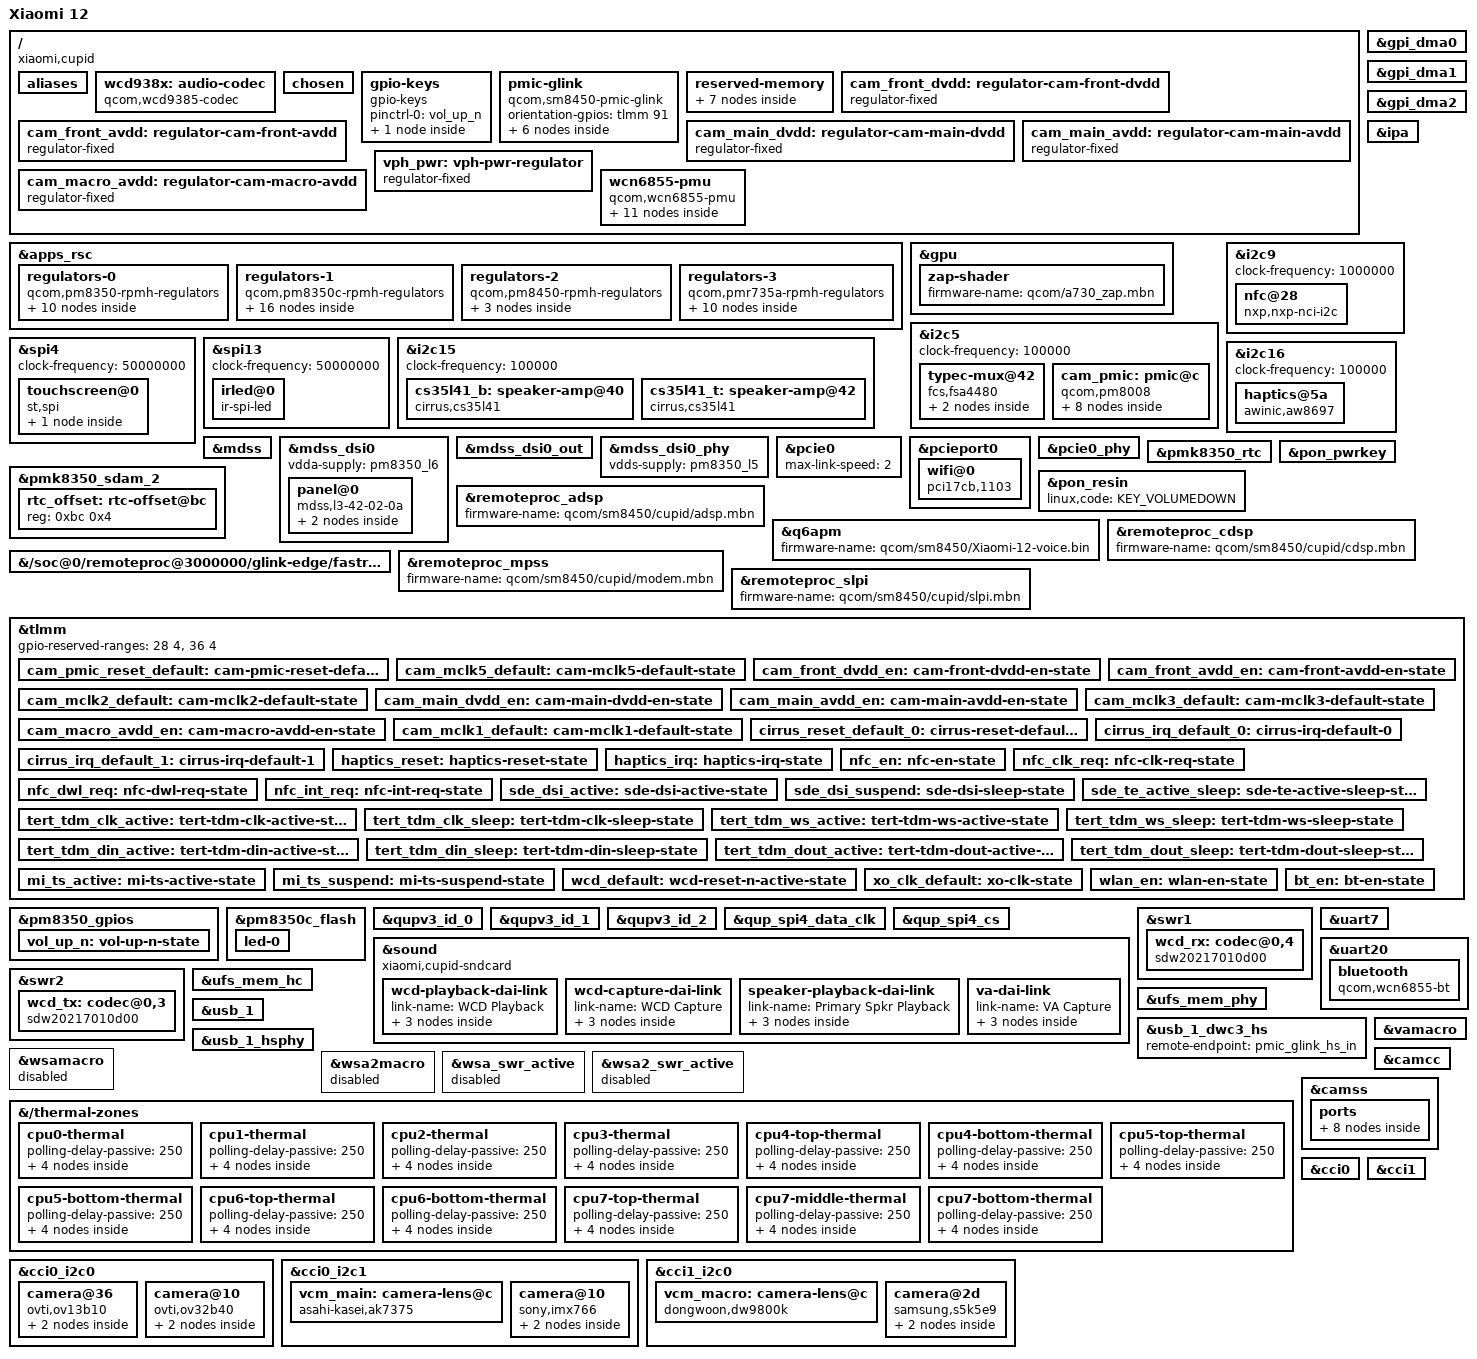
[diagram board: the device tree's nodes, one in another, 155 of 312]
// SPDX-License-Identifier: GPL-2.0-only
/dts-v1/;

#include <dt-bindings/regulator/qcom,rpmh-regulator.h>
#include <dt-bindings/leds/common.h>
#include <dt-bindings/media/video-interfaces.h>
#include <dt-bindings/thermal/thermal.h>

#include "sm8450.dtsi"
#include "pm8350.dtsi"
#include "pm8350b.dtsi"
#include "pm8350c.dtsi"
#include "pm8450.dtsi"
#include "pmk8350.dtsi"
#include "pmr735a.dtsi"

/delete-node/ &xbl_ramdump_mem;
/delete-node/ &xbl_sc_mem2;
/delete-node/ &adsp_mem;
/delete-node/ &rmtfs_mem;

/ {
	model = "Xiaomi 12";
	compatible = "xiaomi,cupid", "qcom,sm8450";
	chassis-type = "handset";

	/*
	 * Qualcomm's ABL matches these against SMEM before it will boot a dtb.
	 * Copied verbatim from the stock cupid devicetree. Without them the
	 * bootloader resets in a loop without any output.
	 */
	qcom,msm-id = <457 0x20000 482 0x20000 457 0x10000 482 0x10000>;
	qcom,board-id = <0x10008 0>;

	aliases {
		hsuart0 = &uart20;
		serial0 = &uart7;
	};

	wcd938x: audio-codec {
		compatible = "qcom,wcd9385-codec";

		pinctrl-names = "default";
		pinctrl-0 = <&wcd_default>;

		qcom,micbias1-microvolt = <2750000>;
		qcom,micbias2-microvolt = <2750000>;
		qcom,micbias3-microvolt = <2750000>;
		qcom,micbias4-microvolt = <2750000>;
		qcom,mbhc-buttons-vthreshold-microvolt = <75000 150000 237000 500000 500000 500000 500000 500000>;
		qcom,mbhc-headset-vthreshold-microvolt = <1700000>;
		qcom,mbhc-headphone-vthreshold-microvolt = <50000>;
		qcom,rx-device = <&wcd_rx>;
		qcom,tx-device = <&wcd_tx>;

		reset-gpios = <&tlmm 43 GPIO_ACTIVE_LOW>;

		vdd-buck-supply = <&pm8350_s10>;
		vdd-rxtx-supply = <&pm8350_s10>;
		vdd-io-supply = <&pm8350_s10>;
		vdd-mic-bias-supply = <&vreg_bob>;

		#sound-dai-cells = <1>;
	};

	chosen {
		#address-cells = <2>;
		#size-cells = <2>;
		ranges;

		bootargs = "earlycon clk_ignore_unused pd_ignore_unused console=tty0";
		stdout-path = "serial0:115200n8";
	};

	gpio-keys {
		compatible = "gpio-keys";

		pinctrl-0 = <&vol_up_n>;
		pinctrl-names = "default";

		key-volume-up {
			label = "Volume Up";
			linux,code = <KEY_VOLUMEUP>;
			gpios = <&pm8350_gpios 6 GPIO_ACTIVE_LOW>;
			debounce-interval = <15>;
			linux,can-disable;
			wakeup-source;
		};
	};

	pmic-glink {
		compatible = "qcom,sm8450-pmic-glink", "qcom,pmic-glink";
		#address-cells = <1>;
		#size-cells = <0>;
		orientation-gpios = <&tlmm 91 GPIO_ACTIVE_HIGH>;

		connector@0 {
			compatible = "usb-c-connector";
			reg = <0>;
			power-role = "dual";
			data-role = "dual";

			ports {
				#address-cells = <1>;
				#size-cells = <0>;

				port@0 {
					reg = <0>;

					pmic_glink_hs_in: endpoint {
						remote-endpoint = <&usb_1_dwc3_hs>;
					};
				};

				// USB3 not present, so no port@1

				port@2 {
					reg = <2>;

					pmic_glink_sbu: endpoint {
						remote-endpoint = <&fsa4480_sbu_mux>;
					};
				};
			};
		};
	};

	reserved-memory {
		/*
		 * Heap of the ADSP's static audio PD, handed over when the PD
		 * is created (FASTRPC_IOCTL_INIT_CREATE_STATIC "audiopd"). The
		 * audio PD loads dynamic modules such as the voice ECNS from
		 * the DSP partition through it. fastrpc assigns the whole
		 * region to LPASS/ADSP_HEAP at probe, so it must be no-map:
		 * as a reusable (CMA) pool like on kodiak, the page allocator
		 * kept lending its pages to Linux, and touching one ended in a
		 * synchronous external abort (crashes under memory pressure).
		 */
		adsp_rpc_remote_heap_mem: adsp-rpc-remote-heap {
			alloc-ranges = <0x0 0x80000000 0x0 0x80000000>;
			alignment = <0x0 0x400000>;
			size = <0x0 0x800000>;
			no-map;
		};

		xbl_ramdump_mem: memory@a6b80000 {
			reg = <0x0 0xa6b80000 0x0 0x280000>;
			no-map;
		};

		xbl_sc_mem2: memory@a6e00000 {
			reg = <0x0 0xa6e00000 0x0 0x40000>;
			no-map;
		};

		adsp_mem: memory@9fd00000 {
			reg = <0x0 0x9fd00000 0x0 0x3100000>;
			no-map;
		};

		/*
		 * The rmtfs memory region in downstream is 'dynamically allocated'
		 * but given the same address every time. Hard code it as this address is
		 * where the modem firmware expects it to be.
		 */
		rmtfs_mem: memory@fe200000 {
			compatible = "qcom,rmtfs-mem";
			reg = <0x0 0xfe200000 0x0 0x280000>;
			no-map;

			qcom,client-id = <1>;
			qcom,vmid = <QCOM_SCM_VMID_MSS_MSA>;
		};

		splash_region@b8000000 {
			reg = <0x0 0xb8000000 0x0 0x2b00000>;
			no-map;
		};

		ramoops@a7000000 {
			compatible = "ramoops";
			reg = <0 0xa7000000 0x0 0x400000>;
			console-size = <0x200000>;
			pmsg-size = <0x200000>;
			ecc-size = <16>;
			no-map;
		};
	};

	/* front camera rails, external LDOs switched by TLMM (stock CAMERA_F_DVDD/AVDD) */
	cam_front_dvdd: regulator-cam-front-dvdd {
		compatible = "regulator-fixed";
		regulator-name = "cam_front_dvdd";
		regulator-min-microvolt = <1100000>;
		regulator-max-microvolt = <1100000>;
		gpio = <&tlmm 93 GPIO_ACTIVE_HIGH>;
		enable-active-high;
		vin-supply = <&pm8350_s12>;
		pinctrl-0 = <&cam_front_dvdd_en>;
		pinctrl-names = "default";
	};

	cam_front_avdd: regulator-cam-front-avdd {
		compatible = "regulator-fixed";
		regulator-name = "cam_front_avdd";
		regulator-min-microvolt = <2800000>;
		regulator-max-microvolt = <2800000>;
		gpio = <&tlmm 68 GPIO_ACTIVE_HIGH>;
		enable-active-high;
		vin-supply = <&vreg_bob>;
		pinctrl-0 = <&cam_front_avdd_en>;
		pinctrl-names = "default";
	};

	/* main camera rails, external LDOs switched by TLMM (stock CAMERA_W_DVDD/AVDD) */
	cam_main_dvdd: regulator-cam-main-dvdd {
		compatible = "regulator-fixed";
		regulator-name = "cam_main_dvdd";
		regulator-min-microvolt = <1104000>;
		regulator-max-microvolt = <1104000>;
		gpio = <&tlmm 2 GPIO_ACTIVE_HIGH>;
		enable-active-high;
		vin-supply = <&pm8350_s12>;
		pinctrl-0 = <&cam_main_dvdd_en>;
		pinctrl-names = "default";
	};

	cam_main_avdd: regulator-cam-main-avdd {
		compatible = "regulator-fixed";
		regulator-name = "cam_main_avdd";
		regulator-min-microvolt = <1800000>;
		regulator-max-microvolt = <1800000>;
		gpio = <&tlmm 70 GPIO_ACTIVE_HIGH>;
		enable-active-high;
		vin-supply = <&pm8350c_s1>;
		pinctrl-0 = <&cam_main_avdd_en>;
		pinctrl-names = "default";
	};

	/* telemacro analog, external LDO switched by TLMM (stock CAMERA_M_AVDD) */
	cam_macro_avdd: regulator-cam-macro-avdd {
		compatible = "regulator-fixed";
		regulator-name = "cam_macro_avdd";
		regulator-min-microvolt = <2800000>;
		regulator-max-microvolt = <2800000>;
		gpio = <&tlmm 71 GPIO_ACTIVE_HIGH>;
		enable-active-high;
		vin-supply = <&vreg_bob>;
		pinctrl-0 = <&cam_macro_avdd_en>;
		pinctrl-names = "default";
	};

	vph_pwr: vph-pwr-regulator {
		compatible = "regulator-fixed";
		regulator-name = "vph_pwr";
		regulator-min-microvolt = <3700000>;
		regulator-max-microvolt = <3700000>;

		regulator-always-on;
		regulator-boot-on;
	};

	wcn6855-pmu {
		compatible = "qcom,wcn6855-pmu";

		pinctrl-0 = <&bt_en>, <&wlan_en>, <&xo_clk_default>;
		pinctrl-names = "default";

		wlan-enable-gpios = <&tlmm 80 GPIO_ACTIVE_HIGH>;
		bt-enable-gpios = <&tlmm 81 GPIO_ACTIVE_HIGH>;
		/*
		 * XO clock select handshake (stock cnss: qcom,xo-clk-gpio on
		 * gpio204). 7.x's power sequencer drives it around WLAN enable;
		 * without it the chip's boot ROM never took the firmware image
		 * ("MHI did not load image over BHI").
		 */
		xo-clk-gpios = <&tlmm 204 GPIO_ACTIVE_HIGH>;
		swctrl-gpios = <&tlmm 82 GPIO_ACTIVE_HIGH>;

		vddio-supply = <&pm8350_s10>;
		/* stock vdd-wlan-dig (0.95 V); pmr735a_s2 is vdd-wlan-aon -> vddpmumx */
		vddaon-supply = <&pm8350_s11>;
		vddpmu-supply = <&pm8350_s11>;
		vddpmumx-supply = <&pmr735a_s2>;
		vddpmucx-supply = <&pm8350_s11>;
		vddrfa0p95-supply = <&pm8350_s11>;
		vddrfa1p3-supply = <&pm8350_s12>;
		vddrfa1p9-supply = <&pm8350c_s1>;
		vddpcie1p3-supply = <&pm8350_s12>;
		vddpcie1p9-supply = <&pm8350c_s1>;

		regulators {
			vreg_pmu_rfa_cmn_0p8: ldo0 {
				regulator-name = "vreg_pmu_rfa_cmn_0p8";
			};

			vreg_pmu_aon_0p8: ldo1 {
				regulator-name = "vreg_pmu_aon_0p8";
			};

			vreg_pmu_wlcx_0p8: ldo2 {
				regulator-name = "vreg_pmu_wlcx_0p8";
			};

			vreg_pmu_wlmx_0p8: ldo3 {
				regulator-name = "vreg_pmu_wlmx_0p8";
			};

			vreg_pmu_btcmx_0p8: ldo4 {
				regulator-name = "vreg_pmu_btcmx_0p8";
			};

			vreg_pmu_pcie_1p8: ldo5 {
				regulator-name = "vreg_pmu_pcie_1p8";
			};

			vreg_pmu_pcie_0p9: ldo6 {
				regulator-name = "vreg_pmu_pcie_0p9";
			};

			vreg_pmu_rfa_0p8: ldo7 {
				regulator-name = "vreg_pmu_rfa_0p8";
			};

			vreg_pmu_rfa_1p2: ldo8 {
				regulator-name = "vreg_pmu_rfa_1p2";
			};

			vreg_pmu_rfa_1p7: ldo9 {
				regulator-name = "vreg_pmu_rfa_1p7";
			};
		};
	};
};


&apps_rsc {
	regulators-0 {
		compatible = "qcom,pm8350-rpmh-regulators";
		qcom,pmic-id = "b";

		vdd-s1-supply = <&vph_pwr>;
		vdd-s2-supply = <&vph_pwr>;
		vdd-s3-supply = <&vph_pwr>;
		vdd-s4-supply = <&vph_pwr>;
		vdd-s5-supply = <&vph_pwr>;
		vdd-s6-supply = <&vph_pwr>;
		vdd-s7-supply = <&vph_pwr>;
		vdd-s8-supply = <&vph_pwr>;
		vdd-s9-supply = <&vph_pwr>;
		vdd-s10-supply = <&vph_pwr>;
		vdd-s11-supply = <&vph_pwr>;
		vdd-s12-supply = <&vph_pwr>;

		vdd-l1-l4-supply = <&pm8350_s11>;
		vdd-l2-l7-supply = <&vreg_bob>;
		vdd-l3-l5-supply = <&pm8350_s11>;
		vdd-l6-l9-l10-supply = <&pm8350_s12>;

		/*
		 * ARC regulators:
		 * s5 - gfx.lvl
		 * l8 - lcx.lvl
		 */

		pm8350_s10: smps10 {
			regulator-name = "pm8350_s10";
			regulator-min-microvolt = <1800000>;
			regulator-max-microvolt = <1800000>;

			/* WCN6855 rail: keep up so the PCIe link trains with the chip powered */
			regulator-always-on;
			regulator-boot-on;
		};

		/*
		 * WCN6855 rails at the stock/HDK minimums (vdd-wlan-dig 0.966 V,
		 * vdd-wlan-rfa2 1.35 V). With 0.848/1.224 V the regulators sat at
		 * their minimum on 7.x, the chip enumerated, then dropped off the
		 * link while booting its firmware ("MHI did not load image over
		 * BHI" / "Device link is not accessible").
		 */
		pm8350_s11: smps11 {
			regulator-name = "pm8350_s11";
			regulator-min-microvolt = <966000>;
			regulator-max-microvolt = <1104000>;

			/* WCN6855 rail: keep up so the PCIe link trains with the chip powered */
			regulator-always-on;
			regulator-boot-on;
		};

		pm8350_s12: smps12 {
			regulator-name = "pm8350_s12";
			regulator-min-microvolt = <1350000>;
			regulator-max-microvolt = <1400000>;

			/* WCN6855 rail: keep up so the PCIe link trains with the chip powered */
			regulator-always-on;
			regulator-boot-on;
		};

		pm8350_l1: ldo1 {
			regulator-name = "pm8350_l1";
			regulator-min-microvolt = <912000>;
			regulator-max-microvolt = <920000>;
			regulator-initial-mode = <RPMH_REGULATOR_MODE_HPM>;
		};

		pm8350_l2: ldo2 {
			regulator-name = "pm8350_l2";
			regulator-min-microvolt = <3072000>;
			regulator-max-microvolt = <3072000>;
			regulator-initial-mode = <RPMH_REGULATOR_MODE_HPM>;
		};

		pm8350_l3: ldo3 {
			regulator-name = "pm8350_l3";
			regulator-min-microvolt = <904000>;
			regulator-max-microvolt = <904000>;
			regulator-initial-mode = <RPMH_REGULATOR_MODE_HPM>;
		};

		pm8350_l5: ldo5 {
			regulator-name = "pm8350_l5";
			regulator-min-microvolt = <880000>;
			regulator-max-microvolt = <912000>;
			regulator-initial-mode = <RPMH_REGULATOR_MODE_HPM>;
		};

		pm8350_l6: ldo6 {
			regulator-name = "pm8350_l6";
			regulator-min-microvolt = <1200000>;
			regulator-max-microvolt = <1200000>;
			regulator-initial-mode = <RPMH_REGULATOR_MODE_HPM>;
		};

		pm8350_l7: ldo7 {
			regulator-name = "pm8350_l7";
			regulator-min-microvolt = <2504000>;
			regulator-max-microvolt = <2504000>;
			regulator-initial-mode = <RPMH_REGULATOR_MODE_HPM>;
		};

		pm8350_l9: ldo9 {
			regulator-name = "pm8350_l9";
			regulator-min-microvolt = <1200000>;
			regulator-max-microvolt = <1200000>;
			regulator-initial-mode = <RPMH_REGULATOR_MODE_HPM>;
		};
	};

	regulators-1 {
		compatible = "qcom,pm8350c-rpmh-regulators";
		qcom,pmic-id = "c";

		vdd-s1-supply = <&vph_pwr>;
		vdd-s2-supply = <&vph_pwr>;
		vdd-s3-supply = <&vph_pwr>;
		vdd-s4-supply = <&vph_pwr>;
		vdd-s5-supply = <&vph_pwr>;
		vdd-s6-supply = <&vph_pwr>;
		vdd-s7-supply = <&vph_pwr>;
		vdd-s8-supply = <&vph_pwr>;
		vdd-s9-supply = <&vph_pwr>;
		vdd-s10-supply = <&vph_pwr>;

		vdd-l1-l12-supply = <&pm8350c_s1>;
		vdd-l2-l8-supply = <&pm8350c_s1>;
		vdd-l3-l4-l5-l7-l13-supply = <&vreg_bob>;
		vdd-l6-l9-l11-supply = <&vreg_bob>;
		vdd-l10-supply = <&pm8350_s12>;

		vdd-bob-supply = <&vph_pwr>;

		/*
		 * ARC regulators:
		 * s2 - mxc.lvl
		 * s4 - mss.lvl
		 * s6 - cx.lvl
		 */

		pm8350c_s1: smps1 {
			regulator-name = "pm8350c_s1";
			regulator-min-microvolt = <1800000>;
			regulator-max-microvolt = <2024000>;

			/* WCN6855 rail: keep up so the PCIe link trains with the chip powered */
			regulator-always-on;
			regulator-boot-on;
		};

		pm8350c_s10: smps10 {
			regulator-name = "pm8350c_s10";
			regulator-min-microvolt = <1000000>;
			regulator-max-microvolt = <1100000>;
		};

		vreg_bob: bob {
			regulator-name = "vreg_bob";
			regulator-min-microvolt = <3080000>;
			regulator-max-microvolt = <3960000>;
			regulator-initial-mode = <RPMH_REGULATOR_MODE_AUTO>;
		};

		pm8350c_l1: ldo1 {
			regulator-name = "pm8350c_l1";
			regulator-min-microvolt = <1800000>;
			regulator-max-microvolt = <1800000>;
			regulator-initial-mode = <RPMH_REGULATOR_MODE_HPM>;
		};

		pm8350c_l2: ldo2 {
			regulator-name = "pm8350c_l2";
			regulator-min-microvolt = <1800000>;
			regulator-max-microvolt = <1800000>;
			regulator-initial-mode = <RPMH_REGULATOR_MODE_HPM>;

			/* touchscreen vdd: the fts driver never takes a reference on it */
			regulator-always-on;
			regulator-boot-on;
		};

		pm8350c_l3: ldo3 {
			regulator-name = "pm8350c_l3";
			regulator-min-microvolt = <3296000>;
			regulator-max-microvolt = <3304000>;
			regulator-initial-mode = <RPMH_REGULATOR_MODE_HPM>;
		};

		pm8350c_l4: ldo4 {
			regulator-name = "pm8350c_l4";
			regulator-min-microvolt = <1704000>;
			regulator-max-microvolt = <3000000>;
			regulator-initial-mode = <RPMH_REGULATOR_MODE_HPM>;
		};

		pm8350c_l5: ldo5 {
			regulator-name = "pm8350c_l5";
			regulator-min-microvolt = <1704000>;
			regulator-max-microvolt = <3000000>;
			regulator-initial-mode = <RPMH_REGULATOR_MODE_HPM>;
		};

		pm8350c_l6: ldo6 {
			regulator-name = "pm8350c_l6";
			regulator-min-microvolt = <1800000>;
			/* Originally max = 3008000 but SDHCI expects 2960000 */
			regulator-max-microvolt = <2960000>;
			regulator-initial-mode = <RPMH_REGULATOR_MODE_HPM>;
		};

		pm8350c_l7: ldo7 {
			regulator-name = "pm8350c_l7";
			regulator-min-microvolt = <3008000>;
			regulator-max-microvolt = <3304000>;
			regulator-initial-mode = <RPMH_REGULATOR_MODE_HPM>;

			/* touchscreen avdd */
			regulator-always-on;
			regulator-boot-on;
		};

		pm8350c_l8: ldo8 {
			regulator-name = "pm8350c_l8";
			regulator-min-microvolt = <1800000>;
			regulator-max-microvolt = <1800000>;
			regulator-initial-mode = <RPMH_REGULATOR_MODE_HPM>;
		};

		pm8350c_l9: ldo9 {
			regulator-name = "pm8350c_l9";
			regulator-min-microvolt = <2960000>;
			/* Originally max = 3008000 but SDHCI expects 2960000 */
			regulator-max-microvolt = <2960000>;
			regulator-initial-mode = <RPMH_REGULATOR_MODE_HPM>;
		};

		pm8350c_l10: ldo10 {
			regulator-name = "pm8350c_l10";
			regulator-min-microvolt = <1200000>;
			regulator-max-microvolt = <1220000>;
			regulator-initial-mode = <RPMH_REGULATOR_MODE_HPM>;
		};

		pm8350c_l11: ldo11 {
			regulator-name = "pm8350c_l11";
			regulator-min-microvolt = <3200000>;
			regulator-max-microvolt = <3200000>;
			regulator-initial-mode = <RPMH_REGULATOR_MODE_HPM>;

			regulator-always-on;
			regulator-boot-on;
		};

		pm8350c_l12: ldo12 {
			regulator-name = "pm8350c_l12";
			regulator-min-microvolt = <1800000>;
			regulator-max-microvolt = <1968000>;
			regulator-initial-mode = <RPMH_REGULATOR_MODE_HPM>;
		};

		pm8350c_l13: ldo13 {
			regulator-name = "pm8350c_l13";
			regulator-min-microvolt = <3000000>;
			regulator-max-microvolt = <3000000>;
			regulator-initial-mode = <RPMH_REGULATOR_MODE_HPM>;
		};
	};

	regulators-2 {
		compatible = "qcom,pm8450-rpmh-regulators";
		qcom,pmic-id = "h";

		vdd-s1-supply = <&vph_pwr>;
		vdd-s2-supply = <&vph_pwr>;
		vdd-s3-supply = <&vph_pwr>;
		vdd-s4-supply = <&vph_pwr>;
		vdd-s5-supply = <&vph_pwr>;
		vdd-s6-supply = <&vph_pwr>;

		vdd-l2-supply = <&vreg_bob>;
		vdd-l3-supply = <&vreg_bob>;
		vdd-l4-supply = <&vreg_bob>;

		/*
		 * ARC regulators:
		 * S2 - ebi.lvl
		 * S4 - mmcx.lvl
		 * S6 - mx.lvl
		 * L1 - lmx.lvl
		 */

		pm8450_s3: smps3 {
			regulator-name = "pm8450_s3";
			regulator-min-microvolt = <500000>;
			regulator-max-microvolt = <600000>;
		};

		pm8450_l2: ldo2 {
			regulator-name = "pm8450_l2";
			regulator-min-microvolt = <880000>;
			regulator-max-microvolt = <912000>;
			regulator-initial-mode = <RPMH_REGULATOR_MODE_HPM>;
		};

		pm8450_l3: ldo3 {
			regulator-name = "pm8450_l3";
			regulator-min-microvolt = <912000>;
			regulator-max-microvolt = <912000>;
			regulator-initial-mode = <RPMH_REGULATOR_MODE_HPM>;
		};
	};

	regulators-3 {
		compatible = "qcom,pmr735a-rpmh-regulators";
		qcom,pmic-id = "e";

		vdd-s1-supply = <&vph_pwr>;
		vdd-s2-supply = <&vph_pwr>;
		vdd-s3-supply = <&vph_pwr>;

		vdd-l1-l2-supply = <&pmr735a_s2>;
		vdd-l3-supply = <&pmr735a_s1>;
		vdd-l4-supply = <&pm8350c_s1>;
		vdd-l5-l6-supply = <&pm8350c_s1>;
		vdd-l7-bob-supply = <&vreg_bob>;

		pmr735a_s1: smps1 {
			regulator-name = "pmr735a_s1";
			regulator-min-microvolt = <1200000>;
			regulator-max-microvolt = <1296000>;
		};

		pmr735a_s2: smps2 {
			regulator-name = "pmr735a_s2";
			regulator-min-microvolt = <500000>;
			regulator-max-microvolt = <1040000>;

			/* WCN6855 rail: keep up so the PCIe link trains with the chip powered */
			regulator-always-on;
			regulator-boot-on;
		};

		pmr735a_s3: smps3 {
			regulator-name = "pmr735a_s3";
			regulator-min-microvolt = <435000>;
			regulator-max-microvolt = <2352000>;
		};

		pmr735a_l1: ldo1 {
			regulator-name = "pmr735a_l1";
			regulator-min-microvolt = <800000>;
			regulator-max-microvolt = <800000>;
		};

		pmr735a_l2: ldo2 {
			regulator-name = "pmr735a_l2";
			regulator-min-microvolt = <480000>;
			regulator-max-microvolt = <912000>;
		};

		pmr735a_l3: ldo3 {
			regulator-name = "pmr735a_l3";
			regulator-min-microvolt = <1200000>;
			regulator-max-microvolt = <1200000>;
		};

		pmr735a_l4: ldo4 {
			regulator-name = "pmr735a_l4";
			regulator-min-microvolt = <1776000>;
			regulator-max-microvolt = <1776000>;
		};

		pmr735a_l5: ldo5 {
			regulator-name = "pmr735a_l5";
			regulator-min-microvolt = <880000>;
			regulator-max-microvolt = <880000>;
		};

		pmr735a_l6: ldo6 {
			regulator-name = "pmr735a_l6";
			regulator-min-microvolt = <1200000>;
			regulator-max-microvolt = <1200000>;
		};

		pmr735a_l7: ldo7 {
			regulator-name = "pmr735a_l7";
			regulator-min-microvolt = <2800000>;
			regulator-max-microvolt = <2800000>;
		};
	};
};

&gpi_dma0 {
	status = "okay";
};

&gpi_dma1 {
	status = "okay";
};

&gpi_dma2 {
	status = "okay";
};

&gpu {
	status = "okay";

	zap-shader {
		firmware-name = "qcom/a730_zap.mbn";
	};
};

/*
 * IPA v5.1, the modem's data path (rmnet). Without it ModemManager sees the
 * QMI modem but "Failed to find a net port". The AP loads the GSI firmware
 * itself (stock: pas-id 15 "ipa_fws", IPA driver loads it), into the same
 * 0x8b900000 region the stock devicetree reserves. Needs kernel patches
 * 0012 (driver) and 0013 (sm8450.dtsi node).
 */
&ipa {
	qcom,gsi-loader = "self";
	memory-region = <&ipa_fw_mem>;
	firmware-name = "qcom/sm8450/cupid/ipa_fws.mbn";
	status = "okay";
};

&i2c5 {
	clock-frequency = <100000>;
	status = "okay";

	typec-mux@42 {
		compatible = "fcs,fsa4480";
		reg = <0x42>;

		interrupts-extended = <&tlmm 69 IRQ_TYPE_LEVEL_LOW>;

		vcc-supply = <&vreg_bob>;
		mode-switch;
		orientation-switch;

		port {
			fsa4480_sbu_mux: endpoint {
				remote-endpoint = <&pmic_glink_sbu>;
			};
		};
	};

	/* nq @ 64 */

	/*
	 * Camera PMIC "pm8008j" (stock: qcom,i2c-pmic at 0xc and 0xd). Its
	 * reset/enable line is gpio11 (stock pm8008j_active: output-high), no
	 * interrupt is wired. Supplies and LDO ranges from the stock DT; the
	 * second PM8008 ("i" at 0x8) feeds no camera and stays undescribed.
	 */
	cam_pmic: pmic@c {
		compatible = "qcom,pm8008";
		reg = <0xc>;

		reset-gpios = <&tlmm 11 GPIO_ACTIVE_LOW>;
		pinctrl-0 = <&cam_pmic_reset_default>;
		pinctrl-names = "default";

		vdd-l1-l2-supply = <&pm8350_s12>;
		vdd-l3-l4-supply = <&vreg_bob>;
		vdd-l5-supply = <&pm8350c_s1>;
		vdd-l6-supply = <&vreg_bob>;
		vdd-l7-supply = <&vreg_bob>;

		regulators {
			/* telemacro core */
			cam_l1: ldo1 {
				regulator-name = "pm8008j_l1";
				regulator-min-microvolt = <1200000>;
				regulator-max-microvolt = <1200000>;
			};

			/* ultra-wide core */
			cam_l2: ldo2 {
				regulator-name = "pm8008j_l2";
				regulator-min-microvolt = <1200000>;
				regulator-max-microvolt = <1200000>;
			};

			/* ultra-wide analog */
			cam_l3: ldo3 {
				regulator-name = "pm8008j_l3";
				regulator-min-microvolt = <2800000>;
				regulator-max-microvolt = <2800000>;
			};

			/* telemacro autofocus (stock: 2.808 V) */
			cam_l4: ldo4 {
				regulator-name = "pm8008j_l4";
				regulator-min-microvolt = <2808000>;
				regulator-max-microvolt = <2808000>;
			};

			/*
			 * I/O of all four sensors, and the pull-up rail of the
			 * CCI buses. Kept on: while it is off SDA/SCL sit low,
			 * and the first CCI transfer after it comes back times
			 * out (the OV13B10's reset write, so every stream after
			 * the first failed).
			 */
			cam_l5: ldo5 {
				regulator-name = "pm8008j_l5";
				regulator-min-microvolt = <1800000>;
				regulator-max-microvolt = <1800000>;
				regulator-always-on;
			};

			/*
			 * Main camera second analogue rail (stock cam_v_custom1,
			 * 3.1 V), also the OIS supply.
			 */
			cam_l6: ldo6 {
				regulator-name = "pm8008j_l6";
				regulator-min-microvolt = <3104000>;
				regulator-max-microvolt = <3104000>;
			};

			/* main camera autofocus (stock cam_vaf: 3.104 V) */
			cam_l7: ldo7 {
				regulator-name = "pm8008j_l7";
				regulator-min-microvolt = <3104000>;
				regulator-max-microvolt = <3104000>;
			};
		};
	};
};

&i2c9 {
	clock-frequency = <1000000>;
	status = "okay";

	/*
	 * NXP SN100T. Downstream drives it with the "qcom,sn-nci" driver;
	 * mainline talks NCI to it through nxp-nci-i2c, as on the Nothing
	 * Phone (2) (SM8475), which wires it to the same GPIOs.
	 * VDD is pm8350_s10, already always-on for the WCN6855.
	 */
	nfc@28 {
		compatible = "nxp,nxp-nci-i2c";
		reg = <0x28>;

		interrupts-extended = <&tlmm 46 IRQ_TYPE_EDGE_RISING>;

		enable-gpios = <&tlmm 34 GPIO_ACTIVE_HIGH>;
		firmware-gpios = <&tlmm 45 GPIO_ACTIVE_HIGH>;

		pinctrl-0 = <&nfc_en>, <&nfc_clk_req>, <&nfc_dwl_req>,
			    <&nfc_int_req>;
		pinctrl-names = "default";
	};
};

&spi4 {
	clock-frequency = <50000000>;
	status = "okay";

	touchscreen@0 {
		compatible = "st,spi";
		reg = <0x0>;
		interrupt-parent = <&tlmm>;
		interrupts = <21 IRQ_TYPE_LEVEL_LOW>;
		pinctrl-names = "pmx_ts_active", "pmx_ts_suspend";
		pinctrl-0 = <&mi_ts_active>;
		pinctrl-1 = <&mi_ts_suspend>;
		avdd-supply = <&pm8350c_l7>;
		vdd-supply = <&pm8350c_l2>;
		fts,pwr-reg-name = "avdd";
		fts,bus-reg-name = "vdd";
		fts,irq-gpio = <&tlmm 21 IRQ_TYPE_LEVEL_LOW>;
		fts,reset-gpio-enable;
		fts,reset-gpio = <&tlmm 20 GPIO_ACTIVE_HIGH>;
		/*
		 * Passed straight to request_threaded_irq() with a NULL primary
		 * handler, which the core rejects without IRQF_ONESHOT:
		 * 0x2008 = IRQF_TRIGGER_LOW | IRQF_ONESHOT (same value as stock).
		 */
		fts,irq-flags = <0x2008>;
		fts,x-max = <10800>;
		fts,y-max = <24000>;
		fts,support-super-resolution = <1>;
		spi-max-frequency = <12000000>;
		fts,default-fw-name = "st_fts_l3.ftb";
		fts,config-array-size = <1>;

		fts,cfg_0 {
			fts,tp-vendor = <0x42>;
			fts,fw-name = "st_fts_l3.ftb";
			fts,limit-name = "stm_fts_production_limits.csv";
		};
	};
};

&spi13 {
	clock-frequency = <50000000>;
	status = "okay";

	irled@0 {
		compatible = "ir-spi-led";
		reg = <0x0>;
		power-supply = <&vph_pwr>;
		spi-max-frequency = <19200000>;
	};
};

&i2c15 {
	clock-frequency = <100000>;
	status = "okay";

	cs35l41_b: speaker-amp@40 {
		compatible = "cirrus,cs35l41";
		reg = <0x40>;
		interrupt-parent = <&tlmm>;
		interrupts = <118 0x2008>;
		pinctrl-names = "default";
		pinctrl-0 = <&cirrus_reset_default_0 &cirrus_irq_default_0>;
		reset-gpios = <&tlmm 1 GPIO_ACTIVE_HIGH>;
		cirrus,boost-peak-milliamp = <4000>;
		cirrus,boost-ind-nanohenry = <1000>;
		cirrus,boost-cap-microfarad = <15>;
		cirrus,gpio2-src-select = <4>;
		cirrus,gpio2-output-enable;
		cirrus,asp-sdout-hiz = <3>;
		sound-name-prefix = "SpkrRight";
		#sound-dai-cells = <1>;
	};

	cs35l41_t: speaker-amp@42 {
		compatible = "cirrus,cs35l41";
		reg = <0x42>;
		interrupt-parent = <&tlmm>;
		interrupts = <63 0x2008>;
		pinctrl-names = "default";
		pinctrl-0 = <&cirrus_irq_default_1>;
		reset-gpios = <&tlmm 1 GPIO_ACTIVE_HIGH>;
		cirrus,boost-peak-milliamp = <4000>;
		cirrus,boost-ind-nanohenry = <1000>;
		cirrus,boost-cap-microfarad = <15>;
		cirrus,gpio2-src-select = <4>;
		cirrus,gpio2-output-enable;
		cirrus,asp-sdout-hiz = <3>;
		sound-name-prefix = "SpkrLeft";
		#sound-dai-cells = <1>;
	};
};

&i2c16 {
	clock-frequency = <100000>;
	status = "okay";

	/*
	 * Awinic AW8697 LRA driver (patch 0019). The interrupt is described
	 * for completeness; the driver plays from the chip RAM and does not
	 * use it. The first driver version hung probe for 9 minutes on 6.13;
	 * the reworked one initialises from a work item and gives up on the
	 * first I2C error (tested on 7.3, 2026-11-16).
	 */
	haptics@5a {
		compatible = "awinic,aw8697";
		reg = <0x5a>;

		interrupts-extended = <&tlmm 90 IRQ_TYPE_EDGE_FALLING>;
		reset-gpios = <&tlmm 89 GPIO_ACTIVE_LOW>;

		pinctrl-0 = <&haptics_reset>, <&haptics_irq>;
		pinctrl-names = "default";
	};
};

&mdss {
	status = "okay";
};

&mdss_dsi0 {
	vdda-supply = <&pm8350_l6>;
	status = "okay";

	panel@0 {
		compatible = "mdss,l3-42-02-0a";
		reg = <0>;

		reset-gpios = <&tlmm 0 GPIO_ACTIVE_LOW>;
		te-gpios = <&tlmm 86 GPIO_ACTIVE_HIGH>;

		pinctrl-0 = <&sde_dsi_active &sde_te_active_sleep>;
		pinctrl-1 = <&sde_dsi_suspend &sde_te_active_sleep>;
		pinctrl-names = "default", "sleep";

		vddd-supply = <&pm8350c_l10>;
		vci-supply = <&pm8350c_l13>;
		vddio-supply = <&pm8350c_l12>;

		port {
			panel_in: endpoint {
				remote-endpoint = <&mdss_dsi0_out>;
			};
		};
	};
};

&mdss_dsi0_out {
	data-lanes = <0 1 2 3>;
	remote-endpoint = <&panel_in>;
};

&mdss_dsi0_phy {
	vdds-supply = <&pm8350_l5>;
	status = "okay";
};

&pcie0 {
	max-link-speed = <2>;
	status = "okay";
};

&pcieport0 {
	wifi@0 {
		compatible = "pci17cb,1103";
		reg = <0x10000 0x0 0x0 0x0 0x0>;

		vddrfacmn-supply = <&vreg_pmu_rfa_cmn_0p8>;
		vddaon-supply = <&vreg_pmu_aon_0p8>;
		vddwlcx-supply = <&vreg_pmu_wlcx_0p8>;
		vddwlmx-supply = <&vreg_pmu_wlmx_0p8>;
		vddpcie1p8-supply = <&vreg_pmu_pcie_1p8>;
		vddpcie0p9-supply = <&vreg_pmu_pcie_0p9>;
		vddrfa0p8-supply = <&vreg_pmu_rfa_0p8>;
		vddrfa1p2-supply = <&vreg_pmu_rfa_1p2>;
		vddrfa1p8-supply = <&vreg_pmu_rfa_1p7>;
	};
};

&pcie0_phy {
	vdda-phy-supply = <&pm8350_l5>;
	vdda-pll-supply = <&pm8350_l6>;
	status = "okay";
};

&pmk8350_rtc {
	nvmem-cells = <&rtc_offset>;
	nvmem-cell-names = "offset";

	status = "okay";
};

&pmk8350_sdam_2 {
	status = "okay";

	rtc_offset: rtc-offset@bc {
		reg = <0xbc 0x4>;
	};
};

&pon_pwrkey {
	status = "okay";
};

&pon_resin {
	linux,code = <KEY_VOLUMEDOWN>;
	status = "okay";
};

&remoteproc_adsp {
	status = "okay";
	firmware-name = "qcom/sm8450/cupid/adsp.mbn";
};

/*
 * Voice call DSP command sequence for the q6apm voice front end (0042),
 * generated on the phone from its calibration database into
 * /lib/firmware/updates by cupid-voice-firmware.
 */
&q6apm {
	firmware-name = "qcom/sm8450/Xiaomi-12-voice.bin";
};

&{/soc@0/remoteproc@3000000/glink-edge/fastrpc} {
	memory-region = <&adsp_rpc_remote_heap_mem>;
	qcom,vmids = <QCOM_SCM_VMID_LPASS QCOM_SCM_VMID_ADSP_HEAP>;
};

&remoteproc_cdsp {
	status = "okay";
	firmware-name = "qcom/sm8450/cupid/cdsp.mbn";
};

&remoteproc_mpss {
	status = "okay";
	firmware-name = "qcom/sm8450/cupid/modem.mbn";
};

&remoteproc_slpi {
	status = "okay";
	firmware-name = "qcom/sm8450/cupid/slpi.mbn";
};

&tlmm {
	gpio-reserved-ranges = <28 4>, <36 4>;

	cam_pmic_reset_default: cam-pmic-reset-default-state {
		pins = "gpio11";
		function = "gpio";
		drive-strength = <2>;
		bias-disable;
	};

	/* stock cam_sensor_mclk1_active: ultra-wide */
	/* stock cam_sensor_mclk5_active: front */
	cam_mclk5_default: cam-mclk5-default-state {
		pins = "gpio105";
		function = "cam_mclk";
		drive-strength = <2>;
		bias-disable;
	};

	cam_front_dvdd_en: cam-front-dvdd-en-state {
		pins = "gpio93";
		function = "gpio";
		drive-strength = <2>;
		bias-disable;
	};

	cam_front_avdd_en: cam-front-avdd-en-state {
		pins = "gpio68";
		function = "gpio";
		drive-strength = <2>;
		bias-disable;
	};

	/* stock cam_sensor_mclk2_active: main */
	cam_mclk2_default: cam-mclk2-default-state {
		pins = "gpio102";
		function = "cam_mclk";
		drive-strength = <2>;
		bias-disable;
	};

	cam_main_dvdd_en: cam-main-dvdd-en-state {
		pins = "gpio2";
		function = "gpio";
		drive-strength = <2>;
		bias-disable;
	};

	cam_main_avdd_en: cam-main-avdd-en-state {
		pins = "gpio70";
		function = "gpio";
		drive-strength = <2>;
		bias-disable;
	};

	/* stock cam_sensor_mclk3_active: telemacro */
	cam_mclk3_default: cam-mclk3-default-state {
		pins = "gpio103";
		function = "cam_mclk";
		drive-strength = <2>;
		bias-disable;
	};

	cam_macro_avdd_en: cam-macro-avdd-en-state {
		pins = "gpio71";
		function = "gpio";
		drive-strength = <2>;
		bias-disable;
	};

	cam_mclk1_default: cam-mclk1-default-state {
		pins = "gpio101";
		function = "cam_mclk";
		drive-strength = <2>;
		bias-disable;
	};

	cirrus_reset_default_0: cirrus-reset-default-0 {
		pins = "gpio1";
		function = "gpio";
		drive-strength = <16>;
		bias-disable;
		output-high;
	};

	cirrus_irq_default_0: cirrus-irq-default-0 {
		pins = "gpio118";
		function = "gpio";
		drive-strength = <2>;
		bias-pull-up;
	};

	cirrus_irq_default_1: cirrus-irq-default-1 {
		pins = "gpio63";
		function = "gpio";
		drive-strength = <2>;
		bias-pull-up;
	};

	haptics_reset: haptics-reset-state {
		pins = "gpio89";
		function = "gpio";
		drive-strength = <2>;
		bias-disable;
	};

	haptics_irq: haptics-irq-state {
		pins = "gpio90";
		function = "gpio";
		drive-strength = <2>;
		bias-pull-up;
	};

	nfc_en: nfc-en-state {
		pins = "gpio34";
		function = "gpio";
		drive-strength = <2>;
		bias-disable;
	};

	nfc_clk_req: nfc-clk-req-state {
		pins = "gpio35";
		function = "gpio";
		drive-strength = <2>;
		bias-disable;
	};

	nfc_dwl_req: nfc-dwl-req-state {
		pins = "gpio45";
		function = "gpio";
		drive-strength = <2>;
		bias-disable;
	};

	nfc_int_req: nfc-int-req-state {
		pins = "gpio46";
		function = "gpio";
		drive-strength = <2>;
		bias-pull-down;
	};

	sde_dsi_active: sde-dsi-active-state {
		pins = "gpio0";
		function = "gpio";
		drive-strength = <8>;
		bias-disable;
	};

	sde_dsi_suspend: sde-dsi-sleep-state {
		pins = "gpio0";
		function = "gpio";
		drive-strength = <2>;
		bias-pull-down;
	};

	sde_te_active_sleep: sde-te-active-sleep-state {
		pins = "gpio86";
		function = "mdp_vsync";
		drive-strength = <2>;
		bias-pull-down;
	};

	tert_tdm_clk_active: tert-tdm-clk-active-state {
		pins = "gpio121";
		function = "mi2s2_sck";
		drive-strength = <6>;
		bias-disable;
		output-high;
	};

	tert_tdm_clk_sleep: tert-tdm-clk-sleep-state {
		pins = "gpio121";
		function = "gpio";
		drive-strength = <2>;
		bias-pull-down;
	};

	tert_tdm_ws_active: tert-tdm-ws-active-state {
		pins = "gpio123";
		function = "mi2s2_ws";
		drive-strength = <8>;
		bias-disable;
		output-high;
	};

	tert_tdm_ws_sleep: tert-tdm-ws-sleep-state {
		pins = "gpio123";
		function = "gpio";
		drive-strength = <2>;
		bias-pull-down;
	};

	tert_tdm_din_active: tert-tdm-din-active-state {
		pins = "gpio122";
		function = "mi2s2_data0";
		drive-strength = <8>;
		bias-disable;
	};

	tert_tdm_din_sleep: tert-tdm-din-sleep-state {
		pins = "gpio122";
		function = "gpio";
		drive-strength = <2>;
		bias-pull-down;
	};

	tert_tdm_dout_active: tert-tdm-dout-active-state {
		pins = "gpio124";
		function = "mi2s2_data1";
		drive-strength = <8>;
		bias-disable;
	};

	tert_tdm_dout_sleep: tert-tdm-dout-sleep-state {
		pins = "gpio124";
		function = "gpio";
		drive-strength = <2>;
		bias-pull-down;
	};

	mi_ts_active: mi-ts-active-state {
		pins = "gpio20", "gpio21";
		function = "gpio";
		drive-strength = <8>;
		bias-pull-up;
	};

	mi_ts_suspend: mi-ts-suspend-state {
		pins = "gpio20", "gpio21";
		function = "gpio";
		drive-strength = <2>;
		bias-pull-down;
	};

	wcd_default: wcd-reset-n-active-state {
		pins = "gpio43";
		function = "gpio";
		drive-strength = <16>;
		bias-disable;
		output-low;
	};

	xo_clk_default: xo-clk-state {
		pins = "gpio204";
		function = "gpio";
		drive-strength = <16>;
		output-low;
		bias-pull-down;
	};

	/*
	 * Both enables start low, like the HDK: the WCN6855 power sequencer
	 * raises them after the rails and the XO handshake. With WLAN_EN
	 * driven high from the pin state, the chip started before its power
	 * sequence and 7.x's ath11k never got the firmware into it (6.13/6.17
	 * only recovered through patch 0004's extra PERST reset).
	 */
	wlan_en: wlan-en-state {
		pins = "gpio80";
		function = "gpio";
		drive-strength = <16>;
		output-low;
		bias-pull-down;
	};

	bt_en: bt-en-state {
		pins = "gpio81";
		function = "gpio";
		drive-strength = <16>;
		output-low;
		bias-pull-down;
	};
};

&pm8350_gpios {
	vol_up_n: vol-up-n-state {
		pins = "gpio6";
		function = "normal";
		power-source = <1>;
		bias-pull-up;
	};
};

&pm8350c_flash {
	status = "okay";

	led-0 {
		function = LED_FUNCTION_FLASH;
		color = <LED_COLOR_ID_WHITE>;
		led-sources = <1>, <4>;
		led-max-microamp = <500000>;
		flash-max-microamp = <1500000>;
		flash-max-timeout-us = <1280000>;
		default-state = "on";
	};
};

&qupv3_id_0 {
	status = "okay";
};

&qupv3_id_1 {
	status = "okay";
};

&qupv3_id_2 {
	status = "okay";
};

&qup_spi4_data_clk {
	drive-strength = <6>;
	bias-disable;
};

&qup_spi4_cs {
	drive-strength = <16>;
	/delete-property/ bias-disable;
	bias-pull-up;
};

&sound {
	compatible = "xiaomi,cupid-sndcard", "qcom,sm8450-sndcard";
	pinctrl-names = "default", "sleep";
	pinctrl-0 = <&tert_tdm_clk_active &tert_tdm_ws_active
			&tert_tdm_din_active &tert_tdm_dout_active>;
	pinctrl-1 = <&tert_tdm_clk_sleep &tert_tdm_ws_sleep
			&tert_tdm_din_sleep &tert_tdm_dout_sleep>;
	model = "Xiaomi-12";

	/*
	 * Speaker TDM: the stock "qcom,mi2s-tdm-is-hw-vote-needed" core vote,
	 * the DCODEC vote (the LPASS macros only hold theirs while active)
	 * and the tertiary TDM bit clock, held by the card for the backend
	 * session.
	 */
	clocks = <&q6prmcc LPASS_HW_MACRO_VOTE LPASS_CLK_ATTRIBUTE_COUPLE_NO>,
		 <&q6prmcc LPASS_CLK_ID_TER_TDM_IBIT LPASS_CLK_ATTRIBUTE_COUPLE_NO>,
		 <&q6prmcc LPASS_HW_DCODEC_VOTE LPASS_CLK_ATTRIBUTE_COUPLE_NO>;
	clock-names = "tdm-vote", "tdm-bclk", "tdm-dcodec-vote";

	/*
	 * Without any routing DAPM has no path from the codec DAIs to anything
	 * physical and the card plays silence. Taken from sm8450-hdk, which has
	 * the same wcd938x codec and lpass macros. The WSA speaker routes are
	 * dropped: the CS35L41 amps sit on tertiary TDM and wire themselves up
	 * through the codec driver's own routes.
	 */
	audio-routing = "IN1_HPHL", "HPHL_OUT",
			"IN2_HPHR", "HPHR_OUT",
			"AMIC1", "MIC BIAS1",
			"AMIC2", "MIC BIAS2",
			"AMIC3", "MIC BIAS3",
			"AMIC4", "MIC BIAS3",
			"AMIC5", "MIC BIAS4",
			"VA DMIC0", "MIC BIAS3",
			"VA DMIC1", "MIC BIAS3",
			"VA DMIC2", "MIC BIAS1",
			"VA DMIC3", "MIC BIAS1",
			"TX DMIC0", "MIC BIAS3",
			"TX DMIC1", "MIC BIAS3",
			"TX DMIC2", "MIC BIAS1",
			"TX DMIC3", "MIC BIAS1",
			"TX SWR_INPUT0", "ADC1_OUTPUT",
			"TX SWR_INPUT1", "ADC2_OUTPUT",
			"TX SWR_INPUT0", "ADC3_OUTPUT",
			"TX SWR_INPUT1", "ADC4_OUTPUT";
	/*
	audio-routing = "AMIC1", "Analog Mic1",
		"AMIC1", "MIC BIAS1",
		"AMIC2", "Analog Mic2",
		"AMIC2", "MIC BIAS2",
		"AMIC3", "Analog Mic3",
		"AMIC3", "MIC BIAS3",
		"AMIC4", "Analog Mic4",
		"AMIC4", "MIC BIAS3",
		"AMIC5", "Analog Mic5",
		"AMIC5", "MIC BIAS4",
		"VA AMIC1", "Analog Mic1",
		"VA AMIC1", "VA MIC BIAS1",
		"VA AMIC2", "Analog Mic2",
		"VA AMIC2", "VA MIC BIAS2",
		"VA AMIC3", "Analog Mic3",
		"VA AMIC3", "VA MIC BIAS3",
		"VA AMIC4", "Analog Mic4",
		"VA AMIC4", "VA MIC BIAS3",
		"VA AMIC5", "Analog Mic5",
		"VA AMIC5", "VA MIC BIAS4",
		"TX DMIC0", "Digital Mic0",
		"Digital Mic0", "MIC BIAS3",
		"TX DMIC1", "Digital Mic1",
		"Digital Mic1", "MIC BIAS3",
		"TX DMIC2", "Digital Mic2",
		"Digital Mic2", "MIC BIAS1",
		"TX DMIC3", "Digital Mic3",
		"Digital Mic3", "MIC BIAS1",
		"IN1_HPHL", "HPHL_OUT",
		"IN2_HPHR", "HPHR_OUT",
		"IN3_AUX", "AUX_OUT",
		"RX_TX DEC0_INP", "TX DEC0 MUX",
		"RX_TX DEC1_INP", "TX DEC1 MUX",
		"RX_TX DEC2_INP", "TX DEC2 MUX",
		"RX_TX DEC3_INP", "TX DEC3 MUX",
		"TX SWR_INPUT", "WCD_TX_OUTPUT",
		"VA SWR_INPUT", "VA_SWR_CLK",
		"VA SWR_INPUT", "WCD_TX_OUTPUT",
		"VA_AIF1 CAP", "VA_SWR_CLK",
		"VA_AIF2 CAP", "VA_SWR_CLK",
		"VA_AIF3 CAP", "VA_SWR_CLK",
		"VA DMIC0", "Digital Mic0",
		"VA DMIC1", "Digital Mic1",
		"VA DMIC2", "Digital Mic2",
		"VA DMIC3", "Digital Mic3",
		"Digital Mic0", "VA MIC BIAS3",
		"Digital Mic1", "VA MIC BIAS3",
		"Digital Mic2", "VA MIC BIAS1",
		"Digital Mic3", "VA MIC BIAS1";
	*/

	wcd-playback-dai-link {
		link-name = "WCD Playback";

		cpu {
			sound-dai = <&q6apmbedai RX_CODEC_DMA_RX_0>;
		};

		codec {
			sound-dai = <&wcd938x 0>, <&swr1 0>, <&rxmacro 0>;
		};

		platform {
			sound-dai = <&q6apm>;
		};
	};

	wcd-capture-dai-link {
		link-name = "WCD Capture";

		cpu {
			sound-dai = <&q6apmbedai TX_CODEC_DMA_TX_3>;
		};

		codec {
			sound-dai = <&wcd938x 1>, <&swr2 0>, <&txmacro 0>;
		};

		platform {
			sound-dai = <&q6apm>;
		};
	};

	/*
	 * Stock speaker TDM: 96 kHz, 32-bit samples in four 32-bit slots,
	 * top amplifier slot 0, bottom slot 1 (stock also drives slot 2 for
	 * the speaker DSP's ultrasound, unused without its firmware).
	 */
	speaker-playback-dai-link {
		link-name = "Primary Spkr Playback";

		cpu {
			sound-dai = <&q6apmbedai TERTIARY_TDM_RX_0>;
			dai-tdm-slot-num = <4>;
			dai-tdm-slot-width = <32>;
			dai-tdm-slot-rx-mask = <1 1 0 0>;
		};

		codec {
			sound-dai = <&cs35l41_t 0>, <&cs35l41_b 0>;
			dai-tdm-slot-num = <4>;
			dai-tdm-slot-width = <32>;
			dai-tdm-slot-rx-mask = <1 1 0 0>;
		};

		platform {
			sound-dai = <&q6apm>;
		};
	};

	va-dai-link {
		link-name = "VA Capture";

		cpu {
			sound-dai = <&q6apmbedai TX_CODEC_DMA_TX_3>;
		};

		codec {
			sound-dai = <&vamacro 0>;
		};

		platform {
			sound-dai = <&q6apm>;
		};
	};
};

&swr1 {
	status = "okay";

	/* WCD9380 RX */
	wcd_rx: codec@0,4 {
		compatible = "sdw20217010d00";
		reg = <0 4>;
		qcom,rx-port-mapping = <1 2 3 4 5>;
	};
};

&swr2 {
	status = "okay";

	/* WCD9380 TX */
	wcd_tx: codec@0,3 {
		compatible = "sdw20217010d00";
		reg = <0 3>;
		qcom,tx-port-mapping = <1 1 2 3>;
	};
};

&uart7 {
	status = "okay";
};

&uart20 {
	status = "okay";

	bluetooth {
		compatible = "qcom,wcn6855-bt";

		vddrfacmn-supply = <&vreg_pmu_rfa_cmn_0p8>;
		vddaon-supply = <&vreg_pmu_aon_0p8>;
		vddwlcx-supply = <&vreg_pmu_wlcx_0p8>;
		vddwlmx-supply = <&vreg_pmu_wlmx_0p8>;
		vddbtcmx-supply = <&vreg_pmu_btcmx_0p8>;
		vddrfa0p8-supply = <&vreg_pmu_rfa_0p8>;
		vddrfa1p2-supply = <&vreg_pmu_rfa_1p2>;
		vddrfa1p8-supply = <&vreg_pmu_rfa_1p7>;

		max-speed = <3200000>;
	};
};

&ufs_mem_hc {
	status = "okay";

	reset-gpios = <&tlmm 210 GPIO_ACTIVE_LOW>;

	vcc-supply = <&pm8350_l7>;
	vcc-max-microamp = <1100000>;
	vccq-supply = <&pm8350_l9>;
	vccq-max-microamp = <1200000>;
	vdd-hba-supply = <&pm8350_l9>;
};

&ufs_mem_phy {
	status = "okay";

	vdda-phy-supply = <&pm8350_l5>;
	vdda-pll-supply = <&pm8350_l6>;
};

&usb_1 {
	/* USB 2.0 only */
	qcom,select-utmi-as-pipe-clk;
	dr_mode = "otg";
	usb-role-switch;
	maximum-speed = "high-speed";
	/* Remove USB3 phy */
	phys = <&usb_1_hsphy>;
	phy-names = "usb2-phy";
	status = "okay";
};

&usb_1_dwc3_hs {
	remote-endpoint = <&pmic_glink_hs_in>;
};

&usb_1_hsphy {
	vdda-pll-supply = <&pm8350_l5>;
	vdda18-supply = <&pm8350c_l1>;
	vdda33-supply = <&pm8350_l2>;

	status = "okay";
};

&vamacro {
	//pinctrl-0 = <&dmic01_default>, <&dmic02_default>;
	//pinctrl-names = "default";
	vdd-micb-supply = <&pm8350_s10>;
	qcom,dmic-sample-rate = <600000>;

	status = "okay";
};

&wsamacro {
	status = "disabled";
};

&wsa2macro {
	status = "disabled";
};

&wsa_swr_active {
	status = "disabled";
};

&wsa2_swr_active {
	status = "disabled";
};

/*
 * sm8450.dtsi describes the CPU thermal zones and gives the CPUs
 * #cooling-cells, but wires cooling-maps only on the GPU zones. The CPU
 * zones have no passive throttling at all: their only trips sit at 115C and
 * 125C. Under sustained load the SoC would climb straight to a critical trip
 * and shut down instead of stepping frequency down.
 *
 * Bind each CPU zone to its cluster's cpufreq cooling device with an 85C
 * passive trip. Clusters: cpu0-3 A510, cpu4-6 A710, cpu7 X2. 85C is
 * deliberately conservative for a first port.
 */
&{/thermal-zones} {
		cpu0-thermal {
			polling-delay-passive = <250>;

			trips {
				cpu0_alert: trip-point-alert {
					temperature = <85000>;
					hysteresis = <2000>;
					type = "passive";
				};
			};

			cooling-maps {
				map0 {
					trip = <&cpu0_alert>;
					cooling-device =
					<&cpu0 THERMAL_NO_LIMIT THERMAL_NO_LIMIT>,
					<&cpu1 THERMAL_NO_LIMIT THERMAL_NO_LIMIT>,
					<&cpu2 THERMAL_NO_LIMIT THERMAL_NO_LIMIT>,
					<&cpu3 THERMAL_NO_LIMIT THERMAL_NO_LIMIT>;
				};
			};
		};

		cpu1-thermal {
			polling-delay-passive = <250>;

			trips {
				cpu1_alert: trip-point-alert {
					temperature = <85000>;
					hysteresis = <2000>;
					type = "passive";
				};
			};

			cooling-maps {
				map0 {
					trip = <&cpu1_alert>;
					cooling-device =
					<&cpu0 THERMAL_NO_LIMIT THERMAL_NO_LIMIT>,
					<&cpu1 THERMAL_NO_LIMIT THERMAL_NO_LIMIT>,
					<&cpu2 THERMAL_NO_LIMIT THERMAL_NO_LIMIT>,
					<&cpu3 THERMAL_NO_LIMIT THERMAL_NO_LIMIT>;
				};
			};
		};

		cpu2-thermal {
			polling-delay-passive = <250>;

			trips {
				cpu2_alert: trip-point-alert {
					temperature = <85000>;
					hysteresis = <2000>;
					type = "passive";
				};
			};

			cooling-maps {
				map0 {
					trip = <&cpu2_alert>;
					cooling-device =
					<&cpu0 THERMAL_NO_LIMIT THERMAL_NO_LIMIT>,
					<&cpu1 THERMAL_NO_LIMIT THERMAL_NO_LIMIT>,
					<&cpu2 THERMAL_NO_LIMIT THERMAL_NO_LIMIT>,
					<&cpu3 THERMAL_NO_LIMIT THERMAL_NO_LIMIT>;
				};
			};
		};

		cpu3-thermal {
			polling-delay-passive = <250>;

			trips {
				cpu3_alert: trip-point-alert {
					temperature = <85000>;
					hysteresis = <2000>;
					type = "passive";
				};
			};

			cooling-maps {
				map0 {
					trip = <&cpu3_alert>;
					cooling-device =
					<&cpu0 THERMAL_NO_LIMIT THERMAL_NO_LIMIT>,
					<&cpu1 THERMAL_NO_LIMIT THERMAL_NO_LIMIT>,
					<&cpu2 THERMAL_NO_LIMIT THERMAL_NO_LIMIT>,
					<&cpu3 THERMAL_NO_LIMIT THERMAL_NO_LIMIT>;
				};
			};
		};

		cpu4-top-thermal {
			polling-delay-passive = <250>;

			trips {
				cpu4_top_alert: trip-point-alert {
					temperature = <85000>;
					hysteresis = <2000>;
					type = "passive";
				};
			};

			cooling-maps {
				map0 {
					trip = <&cpu4_top_alert>;
					cooling-device =
					<&cpu4 THERMAL_NO_LIMIT THERMAL_NO_LIMIT>,
					<&cpu5 THERMAL_NO_LIMIT THERMAL_NO_LIMIT>,
					<&cpu6 THERMAL_NO_LIMIT THERMAL_NO_LIMIT>;
				};
			};
		};

		cpu4-bottom-thermal {
			polling-delay-passive = <250>;

			trips {
				cpu4_bottom_alert: trip-point-alert {
					temperature = <85000>;
					hysteresis = <2000>;
					type = "passive";
				};
			};

			cooling-maps {
				map0 {
					trip = <&cpu4_bottom_alert>;
					cooling-device =
					<&cpu4 THERMAL_NO_LIMIT THERMAL_NO_LIMIT>,
					<&cpu5 THERMAL_NO_LIMIT THERMAL_NO_LIMIT>,
					<&cpu6 THERMAL_NO_LIMIT THERMAL_NO_LIMIT>;
				};
			};
		};

		cpu5-top-thermal {
			polling-delay-passive = <250>;

			trips {
				cpu5_top_alert: trip-point-alert {
					temperature = <85000>;
					hysteresis = <2000>;
					type = "passive";
				};
			};

			cooling-maps {
				map0 {
					trip = <&cpu5_top_alert>;
					cooling-device =
					<&cpu4 THERMAL_NO_LIMIT THERMAL_NO_LIMIT>,
					<&cpu5 THERMAL_NO_LIMIT THERMAL_NO_LIMIT>,
					<&cpu6 THERMAL_NO_LIMIT THERMAL_NO_LIMIT>;
				};
			};
		};

		cpu5-bottom-thermal {
			polling-delay-passive = <250>;

			trips {
				cpu5_bottom_alert: trip-point-alert {
					temperature = <85000>;
					hysteresis = <2000>;
					type = "passive";
				};
			};

			cooling-maps {
				map0 {
					trip = <&cpu5_bottom_alert>;
					cooling-device =
					<&cpu4 THERMAL_NO_LIMIT THERMAL_NO_LIMIT>,
					<&cpu5 THERMAL_NO_LIMIT THERMAL_NO_LIMIT>,
					<&cpu6 THERMAL_NO_LIMIT THERMAL_NO_LIMIT>;
				};
			};
		};

		cpu6-top-thermal {
			polling-delay-passive = <250>;

			trips {
				cpu6_top_alert: trip-point-alert {
					temperature = <85000>;
					hysteresis = <2000>;
					type = "passive";
				};
			};

			cooling-maps {
				map0 {
					trip = <&cpu6_top_alert>;
					cooling-device =
					<&cpu4 THERMAL_NO_LIMIT THERMAL_NO_LIMIT>,
					<&cpu5 THERMAL_NO_LIMIT THERMAL_NO_LIMIT>,
					<&cpu6 THERMAL_NO_LIMIT THERMAL_NO_LIMIT>;
				};
			};
		};

		cpu6-bottom-thermal {
			polling-delay-passive = <250>;

			trips {
				cpu6_bottom_alert: trip-point-alert {
					temperature = <85000>;
					hysteresis = <2000>;
					type = "passive";
				};
			};

			cooling-maps {
				map0 {
					trip = <&cpu6_bottom_alert>;
					cooling-device =
					<&cpu4 THERMAL_NO_LIMIT THERMAL_NO_LIMIT>,
					<&cpu5 THERMAL_NO_LIMIT THERMAL_NO_LIMIT>,
					<&cpu6 THERMAL_NO_LIMIT THERMAL_NO_LIMIT>;
				};
			};
		};

		cpu7-top-thermal {
			polling-delay-passive = <250>;

			trips {
				cpu7_top_alert: trip-point-alert {
					temperature = <85000>;
					hysteresis = <2000>;
					type = "passive";
				};
			};

			cooling-maps {
				map0 {
					trip = <&cpu7_top_alert>;
					cooling-device =
					<&cpu7 THERMAL_NO_LIMIT THERMAL_NO_LIMIT>;
				};
			};
		};

		cpu7-middle-thermal {
			polling-delay-passive = <250>;

			trips {
				cpu7_middle_alert: trip-point-alert {
					temperature = <85000>;
					hysteresis = <2000>;
					type = "passive";
				};
			};

			cooling-maps {
				map0 {
					trip = <&cpu7_middle_alert>;
					cooling-device =
					<&cpu7 THERMAL_NO_LIMIT THERMAL_NO_LIMIT>;
				};
			};
		};

		cpu7-bottom-thermal {
			polling-delay-passive = <250>;

			trips {
				cpu7_bottom_alert: trip-point-alert {
					temperature = <85000>;
					hysteresis = <2000>;
					type = "passive";
				};
			};

			cooling-maps {
				map0 {
					trip = <&cpu7_bottom_alert>;
					cooling-device =
					<&cpu7 THERMAL_NO_LIMIT THERMAL_NO_LIMIT>;
				};
			};
		};
};

/*
 * Cameras, stage 1: the CAMSS receive chain and the ultra-wide.
 *
 * Stock slots (vendor DT + CamX sensor modules):
 *   sensor0 main      Sony IMX766      CCI0 bus 1  CSIPHY2  MCLK2 gpio102  reset gpio126
 *   sensor1 front     OmniVision OV32B40  CCI0 bus 0  CSIPHY3  MCLK5 gpio105  reset gpio127
 *   sensor2 ultra-wide OmniVision OV13B10 CCI0 bus 0  CSIPHY0  MCLK1 gpio101  reset gpio24
 *   sensor3 telemacro Samsung S5K5E9   CCI1 bus 0  CSIPHY1  MCLK3 gpio103  reset gpio128
 * Only the OV13B10 has a mainline driver. All MCLKs run at 19.2 MHz. The
 * CSIPHY rails are pm8350 L5 (0.88 V) and L6 (1.2 V), as on stock.
 */
/*
 * The fork's sm8450.dtsi ships the camera clock controller disabled
 * (mainline enables it); without it neither CCI nor CAMSS get their
 * TITAN_TOP power domain and both fail after the deferred-probe timeout.
 * Mainline also gives it MXC next to MMCX (the camera PLLs run from MXC);
 * with MMCX alone TITAN_TOP_GDSC never powers up ("status stuck at 'off'").
 */
&camcc {
	power-domains = <&rpmhpd RPMHPD_MMCX>,
			<&rpmhpd RPMHPD_MXC>;
	required-opps = <&rpmhpd_opp_low_svs>,
			<&rpmhpd_opp_low_svs>;
	status = "okay";
};

&camss {
	vdda-phy-supply = <&pm8350_l5>;
	vdda-pll-supply = <&pm8350_l6>;
	status = "okay";

	ports {
		port@0 {
			csiphy0_ep: endpoint {
				clock-lanes = <7>;
				data-lanes = <0 1 2 3>;
				bus-type = <MEDIA_BUS_TYPE_CSI2_DPHY>;
				remote-endpoint = <&cam_uw_ep>;
			};
		};

		/* telemacro S5K5E9, stock csiphy-sd-index 1 */
		port@1 {
			csiphy1_ep: endpoint {
				clock-lanes = <7>;
				data-lanes = <0 1>;
				bus-type = <MEDIA_BUS_TYPE_CSI2_DPHY>;
				remote-endpoint = <&cam_macro_ep>;
			};
		};

		/* main IMX766, stock csiphy-sd-index 2, three C-PHY trios */
		port@2 {
			csiphy2_ep: endpoint {
				data-lanes = <0 1 2>;
				bus-type = <MEDIA_BUS_TYPE_CSI2_CPHY>;
				remote-endpoint = <&cam_main_ep>;
			};
		};

		/* front OV32B40, stock csiphy-sd-index 3 */
		port@3 {
			csiphy3_ep: endpoint {
				clock-lanes = <7>;
				data-lanes = <0 1 2 3>;
				bus-type = <MEDIA_BUS_TYPE_CSI2_DPHY>;
				remote-endpoint = <&cam_front_ep>;
			};
		};
	};
};

&cci0 {
	status = "okay";
};

&cci0_i2c0 {
	/*
	 * Ultra-wide, stock qcom,cam-sensor2. The 7-bit address is the
	 * OV13B10 default (0x36, SID low); confirm with a CCI scan.
	 */
	camera@36 {
		compatible = "ovti,ov13b10";
		reg = <0x36>;

		clocks = <&camcc CAM_CC_MCLK1_CLK>;
		assigned-clocks = <&camcc CAM_CC_MCLK1_CLK>;
		assigned-clock-rates = <19200000>;
		clock-frequency = <19200000>;

		reset-gpios = <&tlmm 24 GPIO_ACTIVE_LOW>;
		pinctrl-0 = <&cam_mclk1_default>;
		pinctrl-names = "default";

		dovdd-supply = <&cam_l5>;
		avdd-supply = <&cam_l3>;
		dvdd-supply = <&cam_l2>;

		orientation = <1>;
		rotation = <270>;

		port {
			cam_uw_ep: endpoint {
				data-lanes = <1 2 3 4>;
				link-frequencies = /bits/ 64 <560000000>;
				remote-endpoint = <&csiphy0_ep>;
			};
		};
	};

	/*
	 * Front: OmniVision OV32B40 (stock qcom,cam-sensor1), CCI0 bus 0 at
	 * 0x10 next to the ultra-wide, four lanes into CSIPHY3, MCLK5 at
	 * 19.2 MHz, reset gpio127. Driver and tables from the Xiaomi 14 Ultra
	 * port (same sensor): one 3264x2448 binned mode at 842.4 MHz.
	 */
	camera@10 {
		compatible = "ovti,ov32b40";
		reg = <0x10>;

		clocks = <&camcc CAM_CC_MCLK5_CLK>;
		assigned-clocks = <&camcc CAM_CC_MCLK5_CLK>;
		assigned-clock-rates = <19200000>;

		reset-gpios = <&tlmm 127 GPIO_ACTIVE_LOW>;
		pinctrl-0 = <&cam_mclk5_default>;
		pinctrl-names = "default";

		dovdd-supply = <&cam_l5>;
		avdd-supply = <&cam_front_avdd>;
		dvdd-supply = <&cam_front_dvdd>;

		orientation = <0>;	/* front */
		rotation = <90>;

		port {
			cam_front_ep: endpoint {
				data-lanes = <1 2 3 4>;
				link-frequencies = /bits/ 64 <842400000>;
				remote-endpoint = <&csiphy3_ep>;
			};
		};
	};
};

&cci0_i2c1 {
	/*
	 * Main camera autofocus: AK7314 voice coil driver (stock CamX
	 * cupid_semco_imx766_ak7314_wide_actuator, slave 0x18): the AK7375
	 * register model (position at 0x00, control 0x02: 0x00 active, 0x40
	 * standby).
	 */
	vcm_main: camera-lens@c {
		compatible = "asahi-kasei,ak7375";
		reg = <0x0c>;
		vdd-supply = <&cam_l7>;
		vio-supply = <&cam_l5>;
	};

	/*
	 * Main: Sony IMX766 (stock qcom,cam-sensor0, CamX slave address
	 * 0x20), three C-PHY trios into CSIPHY2, MCLK2 at 19.2 MHz, reset
	 * gpio126. Register tables from the stock CamX sensor module. The
	 * module's OIS (BU24618) and autofocus are not described yet.
	 */
	camera@10 {
		compatible = "sony,imx766";
		reg = <0x10>;

		clocks = <&camcc CAM_CC_MCLK2_CLK>;
		assigned-clocks = <&camcc CAM_CC_MCLK2_CLK>;
		assigned-clock-rates = <19200000>;

		reset-gpios = <&tlmm 126 GPIO_ACTIVE_LOW>;
		pinctrl-0 = <&cam_mclk2_default>;
		pinctrl-names = "default";

		avdd-supply = <&cam_main_avdd>;
		avdd2-supply = <&cam_l6>;
		lens-focus = <&vcm_main>;
		dvdd-supply = <&cam_main_dvdd>;
		dovdd-supply = <&cam_l5>;

		orientation = <1>;	/* back */
		rotation = <270>;

		port {
			cam_main_ep: endpoint {
				bus-type = <MEDIA_BUS_TYPE_CSI2_CPHY>;
				data-lanes = <1 2 3>;
				link-frequencies = /bits/ 64 <856800000>;
				remote-endpoint = <&csiphy2_ep>;
			};
		};
	};
};

&cci1 {
	status = "okay";
};

&cci1_i2c0 {
	/*
	 * Telemacro autofocus: DW9800V (stock CamX
	 * cupid_sunny_s5k5e9_dw9800v_macro_actuator, slave 0x18), programmed
	 * like the DW9800K; the stock module ends its init with SAC mode 2
	 * (0x06 = 0x80) and prescale 5 (0x07 = 0x05).
	 */
	vcm_macro: camera-lens@c {
		compatible = "dongwoon,dw9800k";
		reg = <0x0c>;
		vdd-supply = <&cam_l4>;
		dongwoon,sac-mode = <2>;
		dongwoon,vcm-prescale = <5>;
	};

	/*
	 * Telemacro: Samsung S5K5E9 (stock qcom,cam-sensor3, CamX slave
	 * address 0x5a), two lanes into CSIPHY1, MCLK3 at 19.2 MHz, reset
	 * gpio128. Register tables from the stock CamX sensor module.
	 */
	camera@2d {
		compatible = "samsung,s5k5e9";
		reg = <0x2d>;

		clocks = <&camcc CAM_CC_MCLK3_CLK>;
		assigned-clocks = <&camcc CAM_CC_MCLK3_CLK>;
		assigned-clock-rates = <19200000>;

		reset-gpios = <&tlmm 128 GPIO_ACTIVE_LOW>;
		pinctrl-0 = <&cam_mclk3_default>;
		pinctrl-names = "default";

		avdd-supply = <&cam_macro_avdd>;
		lens-focus = <&vcm_macro>;
		dvdd-supply = <&cam_l1>;
		dovdd-supply = <&cam_l5>;

		orientation = <1>;	/* back */
		rotation = <270>;

		port {
			cam_macro_ep: endpoint {
				data-lanes = <1 2>;
				link-frequencies = /bits/ 64 <438400000>;
				remote-endpoint = <&csiphy1_ep>;
			};
		};
	};
};
